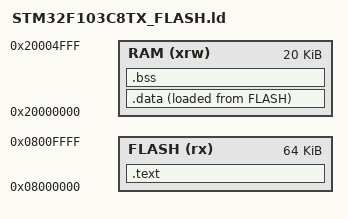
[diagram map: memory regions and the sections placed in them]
/*
******************************************************************************
**
** @file        : LinkerScript.ld
**
** @author      : Auto-generated by STM32CubeIDE
**
** @brief       : Linker script for STM32F103C8Tx Device from STM32F1 series
**                      64KBytes FLASH
**                      20KBytes RAM
**
**                Set heap size, stack size and stack location according
**                to application requirements.
**
**                Set memory bank area and size if external memory is used
**
**  Target      : STMicroelectronics STM32
**
**  Distribution: The file is distributed as is, without any warranty
**                of any kind.
**
******************************************************************************
** @attention
**
** Copyright (c) 2024 STMicroelectronics.
** All rights reserved.
**
** This software is licensed under terms that can be found in the LICENSE file
** in the root directory of this software component.
** If no LICENSE file comes with this software, it is provided AS-IS.
**
******************************************************************************
*/

/* Entry Point */
ENTRY(Reset_Handler)

_Min_Heap_Size = 0x200; /* required amount of heap */
_Min_Stack_Size = 0x400; /* required amount of stack */

/* Memories definition */
MEMORY
{
	RAM    (xrw)    : ORIGIN = 0x20000000,   LENGTH = 20K
	FLASH    (rx)    : ORIGIN = 0x8000000,   LENGTH = 64K
}

/* Sections */
SECTIONS
{
	.text :
	{	/* '.' = VMA = 0x08000000 */
		*(.isr_vector)
		*(.text)
		*(.rodata)
		. = ALIGN(4);
		_etext = .;		/* store the updated location counter value into a symbol '_etext' */	
	}> FLASH

	/* Initialized data sections into "RAM" Ram type memory */
	.data :
	{
		. = ALIGN(4);
		_sdata = .;        /* create a global symbol at data start */
		*(.data)           /* .data sections */
		. = ALIGN(4);
		_edata = .;        /* define a global symbol at data end */
	} >RAM AT> FLASH

	.bss :
	{
		/* This is used by the startup in order to initialize the .bss section */
		_sbss = .;         /* define a global symbol at bss start */
		*(.bss)
		*(COMMON)
		. = ALIGN(4);
		_ebss = .;         /* define a global symbol at bss end */
	} >RAM
}
